# M058SAN_v1 register map
File version: 1.0
Registers are 32-bit, read-write, reset 0x0 unless marked. A register's access mark holds for its fields unless they carry their own. Offsets are from the block's base; [hi:lo] are bit positions; {n}, {i} and the like mark numbered series; 'fields as' and 'values as' point back to an identical list.

## GP — GP Register Map
Base 0x50004000
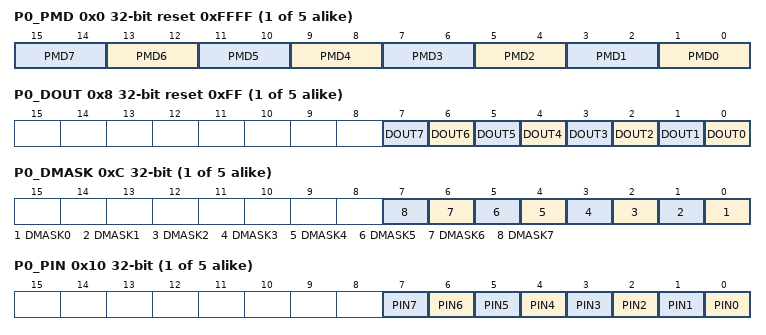
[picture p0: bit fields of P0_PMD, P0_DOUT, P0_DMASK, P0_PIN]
{0x0+0x40*i} P{i}_PMD reset 0xFFFF (i=0..4) — P{i} Pin I/O Mode Control
  [all] fields
    0=Px [n] pin is in INPUT mode; 1=Px [n] pin is in OUTPUT mode; 2=Px [n] pin is in Open-Drain mode; 3=Px [n] pin is in Quasi-bidirectional mode
  [2n+1:2n] PMD{n} (n=0..7) — Px I/O Pin[n] Mode Control. Determine each I/O type of Px pins
{0x4+0x40*i} P{i}_OFFD (i=0..4) — P{i} Digital Input Path Disable Control
  [23:16] OFFD — OFFD: Px Pin[n] Digital Input Path Disable Control
    0=Enable IO digital input path; 1=Disable IO digital input path (digital input tied to low)
{0x8+0x40*i} P{i}_DOUT reset 0xFF (i=0..4) — P{i} Data Output Value
  [all] fields
    0=Px Pin[n] will drive Low if the corresponding output mode enabling bit is set; 1=Px Pin[n] will drive High if the corresponding output mode enabling bit is set
  [n] DOUT{n} (n=0..7) — Px Pin[n] Output Value. Each of these bits control the status of a Px pin when the Px pin is configures as output, open-drain and quasi-mode.
{0xC+0x40*i} P{i}_DMASK (i=0..4) — P{i} Data Output Write Mask
  [all] fields
    0=The corresponding Px_DOUT[n] bit can be updated; 1=The corresponding Px_DOUT[n] bit is protected
  [n] DMASK{n} (n=0..7) — Px Data Output Write Mask (write-protected). These bits are used to protect the corresponding register of Px_DOUT bit[n]. When set the DMASK bit[n] to 1, the corresponding Px_DOUT[n] bit is protected. The write signal is masked, write data to the protect bit is ignored. Note: This function only protect corresponding Px_DOUT[n] bit, and will not protect corresponding bit control register (P0x_DOUT, P1x_DOUT, P2x_DOUT, P3x_DOUT, P4x_DOUT, P5x_DOUT, P6x_DOUT, P7x_DOUT).
{0x10+0x40*i} P{i}_PIN ro (reset mask 0xFFFFFF00) (i=0..4) — P{i} Pin Value
  [n] PIN{n} (n=0..7) — Px Pin Values. The value read from each of these bit reflects the actual status of the respective Px pin
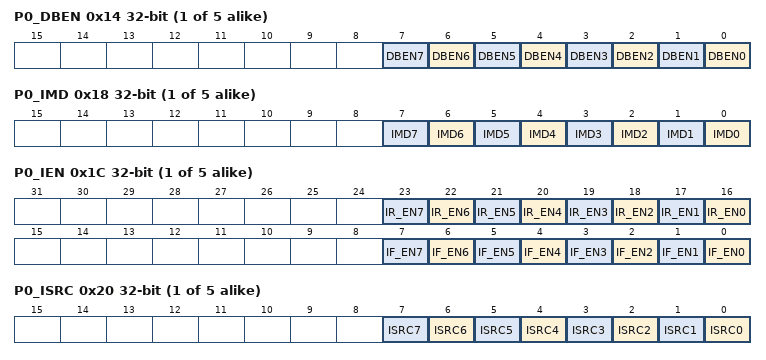
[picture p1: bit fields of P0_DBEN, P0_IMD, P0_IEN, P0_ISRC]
{0x14+0x40*i} P{i}_DBEN (i=0..4) — P{i} De-bounce Enable
  [all] fields
    0=The bit[n] de-bounce function is disabled; 1=The bit[n] de-bounce function is enabled
  [n] DBEN{n} (n=0..7) — Px Input Signal De-bounce Enable. DBEN[n]used to enable the de-bounce function for each corresponding bit. If the input signal pulse width can't be sampled by continuous two de-bounce sample cycle The input signal transition is seen as the signal bounce and will not trigger the interrupt. The DBEN[n] is used for "edge-trigger" interrupt only, and ignored for "level trigger" interrupt. Note: It is recommended setting this bit to '0' if GPIO is chosen as power down wakeup source. If set this bit to '1', will cause GPIO to produce interrupt twice. One is caused by wake up event, the other one is caused by delayed de-bounce result.
{0x18+0x40*i} P{i}_IMD (i=0..4) — P{i} Interrupt Mode Control
  [all] fields
    0=Edge trigger interrupt; 1=Level trigger interrupt
  [n] IMD{n} (n=0..7) — Port 0-7 Interrupt Mode Control. IMD[n] is used to control the interrupt is by level trigger or by edge trigger. If the interrupt is by edge trigger, the trigger source can be controlled by de-bounce. If the interrupt is by level trigger, the input source is sampled by one HCLK clock and generates the interrupt.
{0x1C+0x40*i} P{i}_IEN (i=0..4) — P{i} Interrupt Enable
  [n+16] IR_EN{n} (n=0..7) — Port 0-7 Interrupt Enable by Input Rising Edge or Input Level High. IR_EN[n] used to enable the interrupt for each of the corresponding input Px[n]. Set bit "1" also enable the pin wakeup function. When set the IR_EN[n] bit "1": If the interrupt is level mode trigger, the input Px[n] state at level "high" will generate the interrupt. If the interrupt is edge mode trigger, the input Px[n] state change from "low-to-high" will generate the interrupt.
    0=Disable the Px[n] level-high or low-to-high interrupt; 1=Enable the Px[n] level-high or low-to-high interrupt
  [n] IF_EN{n} (n=0..7) — Port 0-7 Interrupt Enable by Input Falling Edge or Input Level Low. IF_EN[n] used to enable the interrupt for each of the corresponding input Px[n]. Set bit "1" also enable the pin wakeup function. When set the IF_EB[n] bit "1": If the interrupt is level mode trigger, the input Px[n] state at level "low" will generate the interrupt. If the interrupt is edge mode trigger, the input Px[n] state change from "high-to-low" will generate the interrupt.
    0=Disable the Px[n] state low-level or high-to-low change interrupt; 1=Enable the Px[n] state low-level or high-to-low change interrupt
{0x20+0x40*i} P{i}_ISRC (i=0..4) — P{i} Interrupt Source Flag
  [all] fields
    0=No interrupt at Px[n]. No action; 1=Indicates Px[n] generate an interrupt. Clear the correspond pending interrupt
  [n] ISRC{n} (n=0..7) — Port 0-7 Interrupt Source Flag. Read :
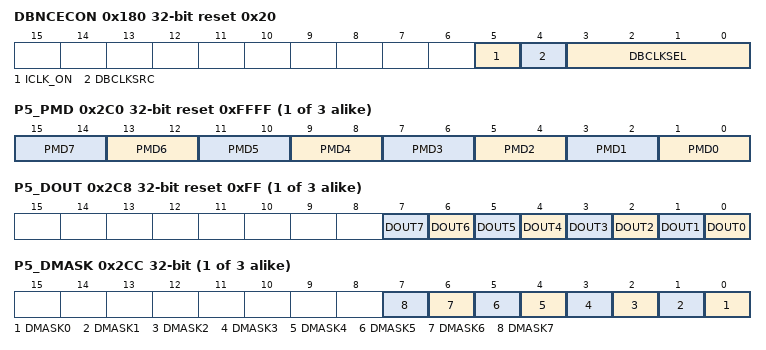
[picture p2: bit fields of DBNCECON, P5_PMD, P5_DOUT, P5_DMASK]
0x180 DBNCECON reset 0x20 — De-bounce Cycle Control
  [5] ICLK_ON — Interru. It is recommended to turn off this bit to save system power, if on special application concern.
    0=Edge detection circuit is active only if IO pin corresponding GPIOx_IEN bit is set to 1; 1=All IO pins edge detection circuit is always active after reset
  [4] DBCLKSRC — De-bounce counter clock source select
    0=De-bounce counter clock source is the HCLK; 1=De-bounce counter clock source is the internal 10kHz clock
  [3:0] DBCLKSEL — De-bounce sampling cycle selection
0x200 P00_DOUT reset 0x1 — P0.0 Data Output Value
  [0] Pxn_PDIO — GPIO Px.n Pin Data Input/Output. Write this bit can control one GPIO pin output value. Read this register to get GPIO pin status. For example: write P00_PDIO will reflect the written value to bit P0_DOUT[0], read P00_PDIO will return the value of P0_PIN[0]. Note: The write operation will not be affected by register Px_DMASK
    0=Set corresponding GPIO pin to low; 1=Set corresponding GPIO pin to high
0x204 P01_DOUT reset 0x1 — P0.1 Data Output Value
  fields as P00_DOUT
0x208 P02_DOUT reset 0x1 — P0.2 Data Output Value
  fields as P00_DOUT
0x20C P03_DOUT reset 0x1 — P0.3 Data Output Value
  fields as P00_DOUT
0x210 P04_DOUT reset 0x1 — P0.4 Data Output Value
  fields as P00_DOUT
0x214 P05_DOUT reset 0x1 — P0.5 Data Output Value
  fields as P00_DOUT
0x218 P06_DOUT reset 0x1 — P0.6 Data Output Value
  fields as P00_DOUT
0x21C P07_DOUT reset 0x1 — P0.7 Data Output Value
  fields as P00_DOUT
0x220 P10_DOUT reset 0x1 — P1.0 Data Output Value
  fields as P00_DOUT
0x224 P11_DOUT reset 0x1 — P1.1 Data Output Value
  fields as P00_DOUT
0x228 P12_DOUT reset 0x1 — P1.2 Data Output Value
  fields as P00_DOUT
0x22C P13_DOUT reset 0x1 — P1.3 Data Output Value
  fields as P00_DOUT
0x230 P14_DOUT reset 0x1 — P1.4 Data Output Value
  fields as P00_DOUT
0x234 P15_DOUT reset 0x1 — P1.5 Data Output Value
  fields as P00_DOUT
0x238 P16_DOUT reset 0x1 — P1.6 Data Output Value
  fields as P00_DOUT
0x23C P17_DOUT reset 0x1 — P1.7 Data Output Value
  fields as P00_DOUT
0x240 P20_DOUT reset 0x1 — P2.0 Data Output Value
  fields as P00_DOUT
0x244 P21_DOUT reset 0x1 — P2.1 Data Output Value
  fields as P00_DOUT
0x248 P22_DOUT reset 0x1 — P2.2 Data Output Value
  fields as P00_DOUT
0x24C P23_DOUT reset 0x1 — P2.3 Data Output Value
  fields as P00_DOUT
0x250 P24_DOUT reset 0x1 — P2.4 Data Output Value
  fields as P00_DOUT
0x254 P25_DOUT reset 0x1 — P2.5 Data Output Value
  fields as P00_DOUT
0x258 P26_DOUT reset 0x1 — P2.6 Data Output Value
  fields as P00_DOUT
0x25C P27_DOUT reset 0x1 — P2.7 Data Output Value
  fields as P00_DOUT
0x260 P30_DOUT reset 0x1 — P3.0 Data Output Value
  fields as P00_DOUT
0x264 P31_DOUT reset 0x1 — P3.1 Data Output Value
  fields as P00_DOUT
0x268 P32_DOUT reset 0x1 — P3.2 Data Output Value
  fields as P00_DOUT
0x26C P33_DOUT reset 0x1 — P3.3 Data Output Value
  fields as P00_DOUT
0x270 P34_DOUT reset 0x1 — P3.4 Data Output Value
  fields as P00_DOUT
0x274 P35_DOUT reset 0x1 — P3.5 Data Output Value
  fields as P00_DOUT
0x278 P36_DOUT reset 0x1 — P3.6 Data Output Value
  fields as P00_DOUT
0x27C P37_DOUT reset 0x1 — P3.7 Data Output Value
  fields as P00_DOUT
0x280 P40_DOUT reset 0x1 — P4.0 Data Output Value
  fields as P00_DOUT
0x284 P41_DOUT reset 0x1 — P4.1 Data Output Value
  fields as P00_DOUT
0x288 P42_DOUT reset 0x1 — P4.2 Data Output Value
  fields as P00_DOUT
0x28C P43_DOUT reset 0x1 — P4.3 Data Output Value
  fields as P00_DOUT
0x290 P44_DOUT reset 0x1 — P4.4 Data Output Value
  fields as P00_DOUT
0x294 P45_DOUT reset 0x1 — P4.5 Data Output Value
  fields as P00_DOUT
0x298 P46_DOUT reset 0x1 — P4.6 Data Output Value
  fields as P00_DOUT
0x29C P47_DOUT reset 0x1 — P4.7 Data Output Value
  fields as P00_DOUT
{0x180+0x40*i} P{i}_PMD reset 0xFFFF (i=5..7) — P{i} Pin I/O Mode Control
  fields as P0_PMD
{0x184+0x40*i} P{i}_OFFD (i=5..7) — P{i} Digital Input Path Disable Control
  fields as P0_OFFD
{0x188+0x40*i} P{i}_DOUT reset 0xFF (i=5..7) — P{i} Data Output Value
  fields as P0_DOUT
{0x18C+0x40*i} P{i}_DMASK (i=5..7) — P{i} Data Output Write Mask
  fields as P0_DMASK
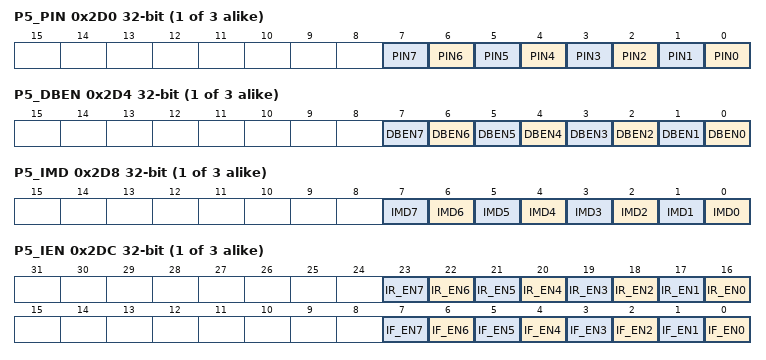
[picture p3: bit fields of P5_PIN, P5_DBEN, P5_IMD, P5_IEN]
{0x190+0x40*i} P{i}_PIN ro (reset mask 0xFFFFFF00) (i=5..7) — P{i} Pin Value
  fields as P0_PIN
{0x194+0x40*i} P{i}_DBEN (i=5..7) — P{i} De-bounce Enable
  fields as P0_DBEN
{0x198+0x40*i} P{i}_IMD (i=5..7) — P{i} Interrupt Mode Control
  fields as P0_IMD
{0x19C+0x40*i} P{i}_IEN (i=5..7) — P{i} Interrupt Enable
  fields as P0_IEN
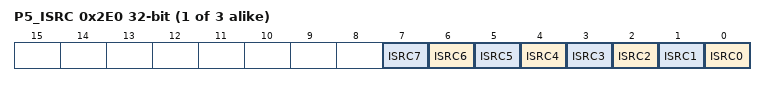
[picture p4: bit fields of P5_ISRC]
{0x1A0+0x40*i} P{i}_ISRC (i=5..7) — P{i} Interrupt Source Flag
  fields as P0_ISRC
0x380 P50_DOUT reset 0x1 — P5.0 Data Output Value
  fields as P00_DOUT
0x384 P51_DOUT reset 0x1 — P5.1 Data Output Value
  fields as P00_DOUT
0x388 P52_DOUT reset 0x1 — P5.2 Data Output Value
  fields as P00_DOUT
0x38C P53_DOUT reset 0x1 — P5.3 Data Output Value
  fields as P00_DOUT
0x390 P54_DOUT reset 0x1 — P5.4 Data Output Value
  fields as P00_DOUT
0x394 P55_DOUT reset 0x1 — P5.5 Data Output Value
  fields as P00_DOUT
0x398 P56_DOUT reset 0x1 — P5.6 Data Output Value
  fields as P00_DOUT
0x39C P57_DOUT reset 0x1 — P5.7 Data Output Value
  fields as P00_DOUT
0x3A0 P60_DOUT reset 0x1 — P6.0 Data Output Value
  fields as P00_DOUT
0x3A4 P61_DOUT reset 0x1 — P6.1 Data Output Value
  fields as P00_DOUT
0x3A8 P62_DOUT reset 0x1 — P6.2 Data Output Value
  fields as P00_DOUT
0x3AC P63_DOUT reset 0x1 — P6.3 Data Output Value
  fields as P00_DOUT
0x3B0 P64_DOUT reset 0x1 — P6.4 Data Output Value
  fields as P00_DOUT
0x3B4 P65_DOUT reset 0x1 — P6.5 Data Output Value
  fields as P00_DOUT
0x3B8 P66_DOUT reset 0x1 — P6.6 Data Output Value
  fields as P00_DOUT
0x3BC P67_DOUT reset 0x1 — P6.7 Data Output Value
  fields as P00_DOUT
0x3C0 P70_DOUT reset 0x1 — P7.0 Data Output Value
  fields as P00_DOUT
0x3C4 P71_DOUT reset 0x1 — P7.1 Data Output Value
  fields as P00_DOUT
